# NAVSS0_MAILBOX1_11_ALIAS64K_MAILBOX1_CFG_REGS11 register map
Vendor: Texas Instruments
Peripheral module from a debugger description file (folder J7_AHP).
Registers are 32-bit, read-write, reset 0x0 unless marked. A register's access mark holds for its fields unless they carry their own. Offsets are as the file gives them; lines under a group give offsets from that group; [hi:lo] are bit positions; {n}, {i} and the like mark numbered series; 'fields as' and 'values as' point back to an identical list; <NAME> marks a mode.

## NAVSS0_MAILBOX1_11_ALIAS64K_MAILBOX1_CFG_REGS11
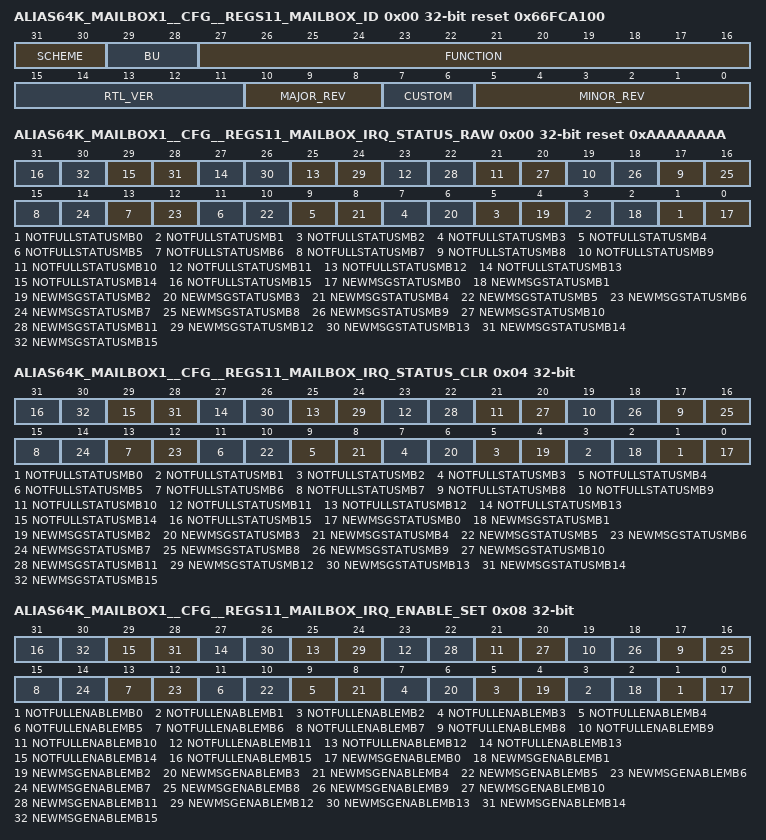
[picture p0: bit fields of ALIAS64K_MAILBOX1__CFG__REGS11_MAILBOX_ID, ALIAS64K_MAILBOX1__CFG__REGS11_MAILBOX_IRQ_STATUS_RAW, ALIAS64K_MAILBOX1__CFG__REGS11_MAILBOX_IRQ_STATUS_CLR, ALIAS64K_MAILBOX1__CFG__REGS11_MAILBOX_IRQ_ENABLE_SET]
0x00 ALIAS64K_MAILBOX1__CFG__REGS11_MAILBOX_ID ro reset 0x66FCA100
  [31:30] SCHEME — Used to distinguish which ID numbering scheme is used.
  [29:28] BU — BU identifier
  [27:16] FUNCTION — Module family.
  [15:11] RTL_VER — RTL version. R of X.Y.R.Z
  [10:8] MAJOR_REV — Major revision. X of X.Y.R.Z
  [7:6] CUSTOM — Special version number
  [5:0] MINOR_REV — Minor revision. Y of X.Y.R.Z
0x00 ALIAS64K_MAILBOX1__CFG__REGS11_MAILBOX_IRQ_STATUS_RAW reset 0xAAAAAAAA
  [2n+1] NOTFULLSTATUSMB{n} (n=0..15) — 1 if Mailbox {n} is not full
  [2n] NEWMSGSTATUSMB{n} (n=0..15) — 1 if there are messages present in Mailbox {n}
0x04 ALIAS64K_MAILBOX1__CFG__REGS11_MAILBOX_IRQ_STATUS_CLR
  [2n+1] NOTFULLSTATUSMB{n} (n=0..15) — 1 if Mailbox {n} is not full and this interrupt bit is enabled
  [2n] NEWMSGSTATUSMB{n} (n=0..15) — 1 if there are messages present in Mailbox {n} and this interrupt bit is enabled
0x08 ALIAS64K_MAILBOX1__CFG__REGS11_MAILBOX_IRQ_ENABLE_SET
  [2n+1] NOTFULLENABLEMB{n} (n=0..15) — Read value is current enable state for this interrupt. Write 1 enables the interrupt. Write 0 does nothing.
  [2n] NEWMSGENABLEMB{n} (n=0..15) — Read value is current enable state for this interrupt. Write 1 enables the interrupt. Write 0 does nothing.
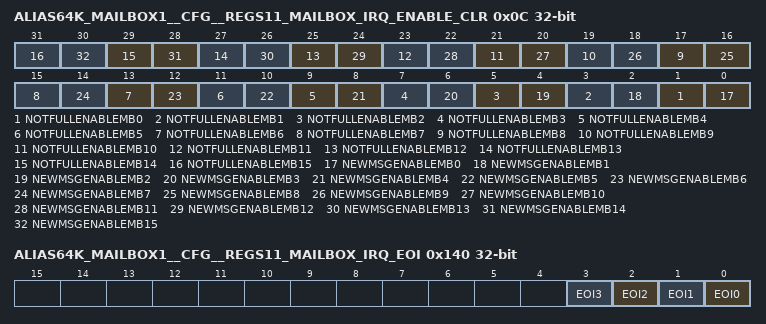
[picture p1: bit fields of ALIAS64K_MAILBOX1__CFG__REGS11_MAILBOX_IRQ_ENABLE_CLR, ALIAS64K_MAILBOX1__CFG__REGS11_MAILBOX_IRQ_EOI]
0x0C ALIAS64K_MAILBOX1__CFG__REGS11_MAILBOX_IRQ_ENABLE_CLR
  [2n+1] NOTFULLENABLEMB{n} (n=0..15) — Read value is current enable state for this interrupt. Write 1 disables the interrupt. Write 0 does nothing.
  [2n] NEWMSGENABLEMB{n} (n=0..15) — Read value is current enable state for this interrupt. Write 1 disables the interrupt. Write 0 does nothing.
0x10 ALIAS64K_MAILBOX1__CFG__REGS11_MAILBOX_SYSCONFIG
  [0] SOFT_RESET — Module Software Reset The bit is automatically reset by the hardware. During reads, it always returns 0. It has the same effect as the hardware reset. Writing a 0 has no effect. Writing a 1 will start a soft reset sequence and empty all the mailboxes
0x40 ALIAS64K_MAILBOX1__CFG__REGS11_MAILBOX_MESSAGE
  [31:0] MESSAGE_VALUE — Message in Mailbox [a]
0x80 ALIAS64K_MAILBOX1__CFG__REGS11_MAILBOX_FIFOSTATUS ro
  [0] FIFO_FULL — Full flag for Mailbox m
0xC0 ALIAS64K_MAILBOX1__CFG__REGS11_MAILBOX_MSGSTATUS ro
  [2:0] NUM_MESSAGES — Number of messages in Mailbox[a]
0x140 ALIAS64K_MAILBOX1__CFG__REGS11_MAILBOX_IRQ_EOI wo
  [n] EOI{n} (n=0..3) — Software EOI signal for the user {n} interrupt
